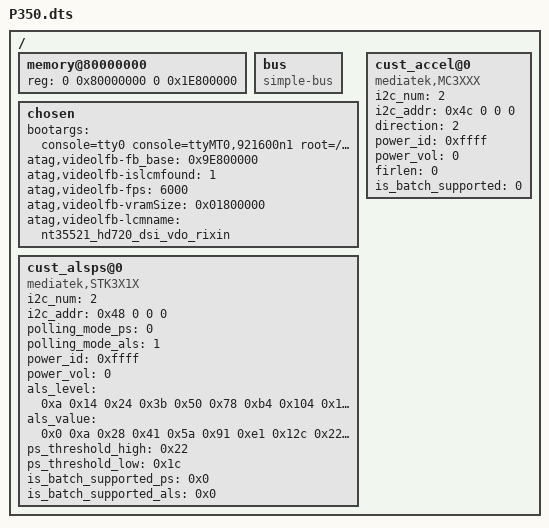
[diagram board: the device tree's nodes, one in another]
/dts-v1/;

/include/ "mt6580.dtsi"
/include/ "cust_eint.dtsi"
/include/ "cust_i2c.dtsi"

/ {
	memory@80000000 {
		device_type = "memory";
		reg = <0 0x80000000 0 0x1E800000>;
	};

	bus {
		compatible = "simple-bus";
		#address-cells = <1>;
		#size-cells = <1>;
		ranges = <0 0 0 0xffffffff>;
	};

    /* chosen */
    chosen {
        bootargs = "console=tty0 console=ttyMT0,921600n1 root=/dev/ram initrd=0x84000000,0x400000 loglevel=8";
		/* fpga may has no lk, we need to specify display info here */
		/* fb buffer is reserved using this dts by memory node above */
		atag,videolfb-fb_base = <0x9E800000>;
		atag,videolfb-islcmfound = <1>;
		atag,videolfb-fps= <6000>;
		atag,videolfb-vramSize= <0x01800000>;
		atag,videolfb-lcmname= "nt35521_hd720_dsi_vdo_rixin";
    };
  /*  start sensor */
		cust_accel@0 {
		compatible 				= "mediatek,MC3XXX";
		i2c_num 				= <2>;
		i2c_addr				= <0x4c 0 0 0>;
		direction 				= <2>;
		power_id 				= <0xffff>;
		power_vol				= <0>;
		firlen 					= <0>;
		is_batch_supported  	= <0>;
  		};
  
		cust_alsps@0 {
		compatible 				= "mediatek,STK3X1X";
		i2c_num 				= <2>;
		i2c_addr 				= <0x48 0 0 0>;
		polling_mode_ps			= <0>;
		polling_mode_als		= <1>;
		power_id   				= <0xffff>;
		power_vol  				= <0>;
		als_level = <0xa 0x14 0x24 0x3b 0x50 0x78 0xb4 0x104 0x1c2 0x34d 0x470 0x609 0x93c 0x122f 0x1b46>;
		als_value = <0x0 0xa 0x28 0x41 0x5a 0x91 0xe1 0x12c 0x226 0x3a2 0x4e2 0x6a4 0xa28 0x1400 0x1e00 0x2800>;
		ps_threshold_high = <0x22>;
		ps_threshold_low = <0x1c>;
		is_batch_supported_ps = <0x0>;
		is_batch_supported_als = <0x0>;
		};
		
  /* end sensor */
};
